# FSS_OSPI_0_OSPI_CFG_0FC44000h register map
Vendor: Texas Instruments
Peripheral module from a debugger description file (folder am62D).
Registers are 32-bit, read-only, reset 0x0 unless marked. A register's access mark holds for its fields unless they carry their own. Offsets are as the file gives them; lines under a group give offsets from that group; [hi:lo] are bit positions; {n}, {i} and the like mark numbered series; 'fields as' and 'values as' point back to an identical list; <NAME> marks a mode.

## ospi_cfg
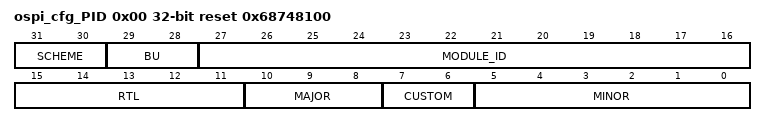
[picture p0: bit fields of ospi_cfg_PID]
0x00 ospi_cfg_PID reset 0x68748100 — The Revision Register contains the major and minor revisions for the module.
  [31:30] SCHEME — PID register scheme Reset Source: psrst_n
  [29:28] BU — Business Unit: 10 = Processors Reset Source: psrst_n
  [27:16] MODULE_ID — Module ID Reset Source: psrst_n
  [15:11] RTL — RTL revision. Will vary depending on release. Reset Source: psrst_n
  [10:8] MAJOR — Major revision Reset Source: psrst_n
  [7:6] CUSTOM — Custom Reset Source: psrst_n
  [5:0] MINOR — Minor revision Reset Source: psrst_n
0x04 ospi_cfg_CTRL rw — The Control Register contains general control bits for the ospi
  [3] PIPELINE_MODE_FLUSH — 1 - Flush Cadence Flash Controller FIFO by forcin gAHB SEL low.0 - AHB Sel to Cadence Controller is 1 Reset Source: psrst_n
0x08 ospi_cfg_STAT — The Status register provide general status bits for the ospi
  [1] MEM_INIT_DONE — 0:Memory Initialization is in progress, 1:Memory Intialization Done Reset Source: psrst_n
0x20 ospi_cfg_EOI wo — End of Interrupt Register
  [7:0] EOI — Write with bit position of targetted interrupt. (E.g. Ext TS is bit 0).Upon write, level interrupt will clear and if unserviced interrupt counter > 1 will issue another pulse interrupt Reset Source: psrst_n
